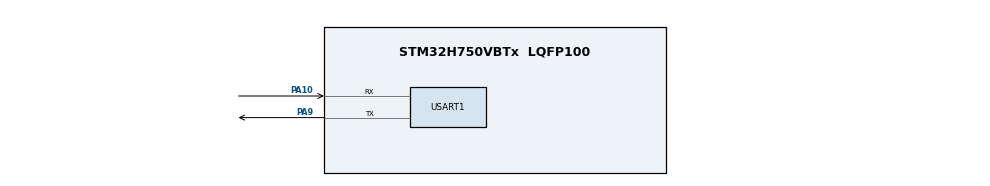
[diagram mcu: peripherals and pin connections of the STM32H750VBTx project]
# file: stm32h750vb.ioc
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Mcu.Family=STM32H7
Mcu.Name=STM32H750VBTx
Mcu.Package=LQFP100
NVIC.PriorityGroup=NVIC_PRIORITYGROUP_4
NVIC.USART1_IRQn=true\:0\:0\:false\:false\:true\:true\:true
PA10.Mode=Asynchronous
PA10.Signal=USART1_RX
PA13\ (JTMS/SWDIO).Mode=Serial_Wire
PA13\ (JTMS/SWDIO).Signal=DEBUG_JTMS-SWDIO
PA14\ (JTCK/SWCLK).Mode=Serial_Wire
PA14\ (JTCK/SWCLK).Signal=DEBUG_JTCK-SWCLK
PA9.Mode=Asynchronous
PA9.Signal=USART1_TX
PH0-OSC_IN\ (PH0).Mode=HSE-External-Oscillator
PH0-OSC_IN\ (PH0).Signal=RCC_OSC_IN
PH1-OSC_OUT\ (PH1).Mode=HSE-External-Oscillator
PH1-OSC_OUT\ (PH1).Signal=RCC_OSC_OUT
ProjectManager.HeapSize=0x2000
ProjectManager.StackSize=0x4000
ProjectManager.TargetToolchain=MDK-ARM V5.32
RCC.ADCFreq_Value=50390625
RCC.APB1Freq_Value=120000000
RCC.APB2Freq_Value=120000000
RCC.APB3Freq_Value=120000000
RCC.APB4Freq_Value=120000000
RCC.CortexFreq_Value=480000000
RCC.D1PPRE=RCC_APB3_DIV2
RCC.D2PPRE1=RCC_APB1_DIV2
RCC.D2PPRE2=RCC_APB2_DIV2
RCC.D3PPRE=RCC_APB4_DIV2
RCC.DIVM1=5
RCC.DIVN1=192
RCC.HCLKFreq_Value=240000000
RCC.HPRE=RCC_HCLK_DIV2
RCC.PLL2FRACN=0
RCC.PLL3FRACN=0
RCC.PLLFRACN=0
RCC.PLLSourceVirtual=RCC_PLLSOURCE_HSE
RCC.PWR_Regulator_Voltage_Scale=PWR_REGULATOR_VOLTAGE_SCALE0
RCC.SYSCLKFreq_VALUE=480000000
RCC.SYSCLKSource=RCC_SYSCLKSOURCE_PLLCLK
RCC.USBFreq_Value=480000000
USART1.VirtualMode-Asynchronous=VM_ASYNC
board=custom

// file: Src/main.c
/* USER CODE BEGIN Header */
/**
  ******************************************************************************
  * @file           : main.c
  * @brief          : Main program body
  ******************************************************************************
  * @attention
  *
  * Copyright (c) 2022 STMicroelectronics.
  * All rights reserved.
  *
  * This software is licensed under terms that can be found in the LICENSE file
  * in the root directory of this software component.
  * If no LICENSE file comes with this software, it is provided AS-IS.
  *
  ******************************************************************************
  */
/* USER CODE END Header */
#include "main.h"
#include "usart.h"
#include "gpio.h"

/* USER CODE BEGIN Includes */
#include "pikaScript.h"
/* USER CODE END Includes */

void SystemClock_Config(void);

/* USER CODE BEGIN 0 */
int fputc(int ch, FILE *f)
{
	uint8_t c = ch;
	HAL_UART_Transmit(&huart1,&c,1,1);
	return ch;
}

char __platform_getchar(void) {
    uint8_t ch;
    while(1){
        if(HAL_OK == HAL_UART_Receive(&huart1, &ch, 1, 0)){
            return ch;
        }
    }
}
/* USER CODE END 0 */

int main(void)
{

  /* MCU Configuration--------------------------------------------------------*/

  /* Reset of all peripherals, Initializes the Flash interface and the Systick. */
  HAL_Init();

  /* Configure the system clock */
  SystemClock_Config();

  /* Initialize all configured peripherals */
  MX_GPIO_Init();
  MX_USART1_UART_Init();
  /* USER CODE BEGIN 2 */
  pikaScriptShell(pikaScriptInit());
  /* USER CODE END 2 */

  /* Infinite loop */
  while (1)
  {

  }
}

void SystemClock_Config(void)
{
  RCC_OscInitTypeDef RCC_OscInitStruct = {0};
  RCC_ClkInitTypeDef RCC_ClkInitStruct = {0};

  /** Supply configuration update enable
  */
  HAL_PWREx_ConfigSupply(PWR_LDO_SUPPLY);
  /** Configure the main internal regulator output voltage
  */
  __HAL_PWR_VOLTAGESCALING_CONFIG(PWR_REGULATOR_VOLTAGE_SCALE0);

  while(!__HAL_PWR_GET_FLAG(PWR_FLAG_VOSRDY)) {}
  /** Initializes the RCC Oscillators according to the specified parameters
  * in the RCC_OscInitTypeDef structure.
  */
  RCC_OscInitStruct.OscillatorType = RCC_OSCILLATORTYPE_HSE;
  RCC_OscInitStruct.HSEState = RCC_HSE_ON;
  RCC_OscInitStruct.PLL.PLLState = RCC_PLL_ON;
  RCC_OscInitStruct.PLL.PLLSource = RCC_PLLSOURCE_HSE;
  RCC_OscInitStruct.PLL.PLLM = 5;
  RCC_OscInitStruct.PLL.PLLN = 192;
  RCC_OscInitStruct.PLL.PLLP = 2;
  RCC_OscInitStruct.PLL.PLLQ = 2;
  RCC_OscInitStruct.PLL.PLLR = 2;
  RCC_OscInitStruct.PLL.PLLRGE = RCC_PLL1VCIRANGE_2;
  RCC_OscInitStruct.PLL.PLLVCOSEL = RCC_PLL1VCOWIDE;
  RCC_OscInitStruct.PLL.PLLFRACN = 0;
  if (HAL_RCC_OscConfig(&RCC_OscInitStruct) != HAL_OK)
  {
    Error_Handler();
  }
  /** Initializes the CPU, AHB and APB buses clocks
  */
  RCC_ClkInitStruct.ClockType = RCC_CLOCKTYPE_HCLK|RCC_CLOCKTYPE_SYSCLK
                              |RCC_CLOCKTYPE_PCLK1|RCC_CLOCKTYPE_PCLK2
                              |RCC_CLOCKTYPE_D3PCLK1|RCC_CLOCKTYPE_D1PCLK1;
  RCC_ClkInitStruct.SYSCLKSource = RCC_SYSCLKSOURCE_PLLCLK;
  RCC_ClkInitStruct.SYSCLKDivider = RCC_SYSCLK_DIV1;
  RCC_ClkInitStruct.AHBCLKDivider = RCC_HCLK_DIV2;
  RCC_ClkInitStruct.APB3CLKDivider = RCC_APB3_DIV2;
  RCC_ClkInitStruct.APB1CLKDivider = RCC_APB1_DIV2;
  RCC_ClkInitStruct.APB2CLKDivider = RCC_APB2_DIV2;
  RCC_ClkInitStruct.APB4CLKDivider = RCC_APB4_DIV2;

  if (HAL_RCC_ClockConfig(&RCC_ClkInitStruct, FLASH_LATENCY_4) != HAL_OK)
  {
    Error_Handler();
  }
}

void Error_Handler(void)
{
  __disable_irq();
  while (1)
  {
  }
}
